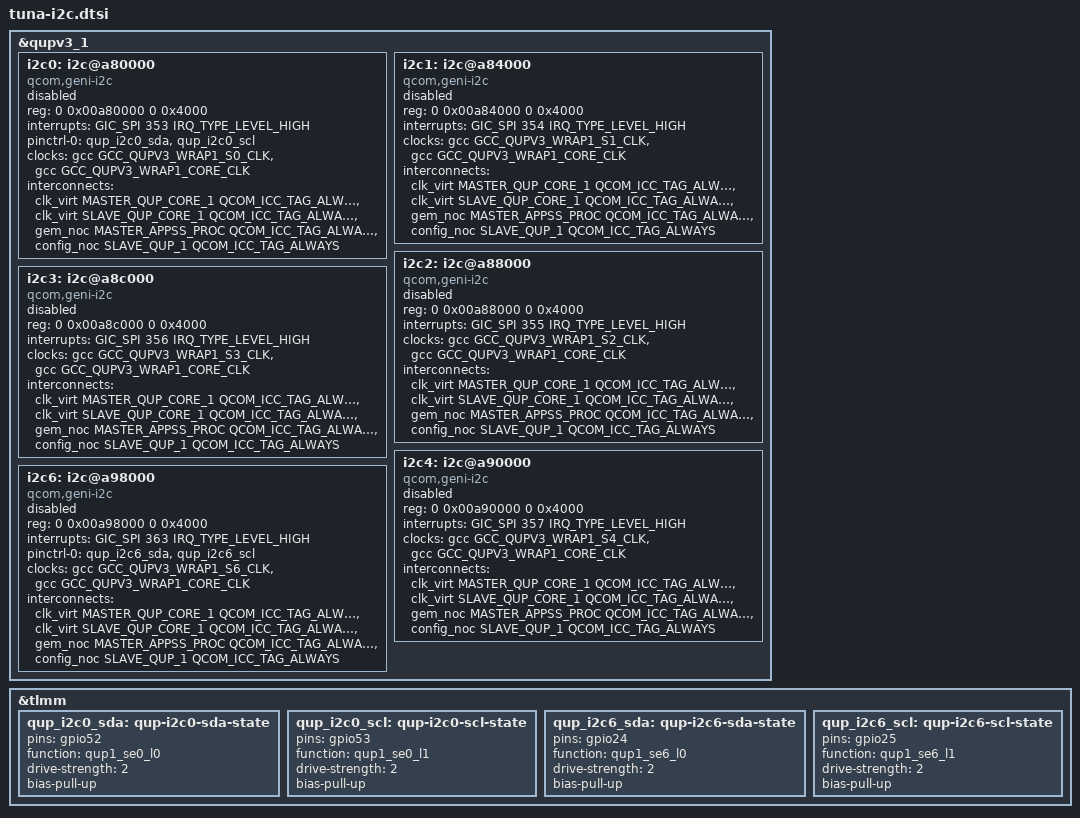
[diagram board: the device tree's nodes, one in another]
// SPDX-License-Identifier: BSD-3-Clause
/*
 * Meizu 22 (M2582) -- the I2C instances inside qupv3 wrap 1.
 *
 * tuna.dtsi already declares qupv3_1 at 0xac0000 and uart7 (SE7) inside it.
 * This adds the I2C controllers that share that wrapper. Addresses and
 * interrupts are taken from the factory device tree, which names the same
 * blocks "qcom,i2c-geni" and calls the clock "se-clk":
 *
 *     SE0  0xa80000  GIC SPI 353   gpio52/53   <- the only one enabled here
 *     SE1  0xa84000  GIC SPI 354   gpio4/5     <- absent from the AP's map
 *     SE2  0xa88000  GIC SPI 355   gpio8/9
 *     SE3  0xa8c000  GIC SPI 356   gpio60/61   (WCD939x codec, factory only)
 *     SE4  0xa90000  GIC SPI 357   gpio16/17
 *     SE6  0xa98000  GIC SPI 363   gpio24/25   <- absent from the AP's map
 *     SE7  0xa9c000  GIC SPI 579   (uart7, declared in tuna.dtsi)
 *
 * The pin numbers are mainline's, from pinctrl-tuna.c, and the factory tree's
 * agree with them instance for instance: its SE0 is on gpio52/53, its SE5 on
 * gpio12/13, its SE6 on gpio24/25. An earlier note here claimed the two tables
 * were offset; that came from a scan which matched the string "gpio" in every
 * pin property of each state node instead of the first, so the factory's SE0
 * read back as gpio28/29. One block at a time gives gpio52/53. Nothing on this
 * board is wired to SE0 or to any other bus in this wrapper -- see
 * meizu-m2582-i2c.dtsi for where the devices actually are.
 *
 * Every instance needs both clocks named. qcom-geni-se.c takes "se" with
 * devm_clk_get() and "core" with devm_clk_get_optional() and enables both
 * before touching a register; with "core" missing the enable silently
 * succeeds on a NULL pointer, the QUP core stays unclocked, and the first
 * register read raises a synchronous external abort.
 *
 * Every instance votes for the QUP core path as well. geni_icc_get() treats the
 * paths as optional, which is a trap here: without a vote on
 * MASTER_QUP_CORE_1 -> SLAVE_QUP_CORE_1 the wrap's QUP core clock is gated, and
 * the first transfer through the controller then wedges the AXI bus. The paths
 * were left out originally on the theory that configuring one made the probe
 * abort; that abort was SE6's dead register window, which is a different
 * problem and is documented below.
 */

&qupv3_1 {
	i2c0: i2c@a80000 {
		compatible = "qcom,geni-i2c";
		reg = <0 0x00a80000 0 0x4000>;
		interrupts = <GIC_SPI 353 IRQ_TYPE_LEVEL_HIGH>;
		/*
		 * SDA/SCL on gpio52/gpio53. SE1 and SE6 are not mapped for the
		 * application processor at all -- the first register access to
		 * either raises a synchronous external abort -- so this is the
		 * bus to use.
		 */
		pinctrl-names = "default";
		pinctrl-0 = <&qup_i2c0_sda>, <&qup_i2c0_scl>;
		clocks = <&gcc GCC_QUPV3_WRAP1_S0_CLK>, <&gcc GCC_QUPV3_WRAP1_CORE_CLK>;
		interconnects = <&clk_virt MASTER_QUP_CORE_1 QCOM_ICC_TAG_ALWAYS
				 &clk_virt SLAVE_QUP_CORE_1 QCOM_ICC_TAG_ALWAYS>,
				<&gem_noc MASTER_APPSS_PROC QCOM_ICC_TAG_ALWAYS
				 &config_noc SLAVE_QUP_1 QCOM_ICC_TAG_ALWAYS>;
		interconnect-names = "qup-core", "qup-config";
		clock-names = "se", "core";
		status = "disabled";
	};

	i2c1: i2c@a84000 {
		compatible = "qcom,geni-i2c";
		reg = <0 0x00a84000 0 0x4000>;
		interrupts = <GIC_SPI 354 IRQ_TYPE_LEVEL_HIGH>;
		clocks = <&gcc GCC_QUPV3_WRAP1_S1_CLK>, <&gcc GCC_QUPV3_WRAP1_CORE_CLK>;
		interconnects = <&clk_virt MASTER_QUP_CORE_1 QCOM_ICC_TAG_ALWAYS
				 &clk_virt SLAVE_QUP_CORE_1 QCOM_ICC_TAG_ALWAYS>,
				<&gem_noc MASTER_APPSS_PROC QCOM_ICC_TAG_ALWAYS
				 &config_noc SLAVE_QUP_1 QCOM_ICC_TAG_ALWAYS>;
		interconnect-names = "qup-core", "qup-config";
		clock-names = "se", "core";
		status = "disabled";
	};

	i2c2: i2c@a88000 {
		compatible = "qcom,geni-i2c";
		reg = <0 0x00a88000 0 0x4000>;
		interrupts = <GIC_SPI 355 IRQ_TYPE_LEVEL_HIGH>;
		clocks = <&gcc GCC_QUPV3_WRAP1_S2_CLK>, <&gcc GCC_QUPV3_WRAP1_CORE_CLK>;
		interconnects = <&clk_virt MASTER_QUP_CORE_1 QCOM_ICC_TAG_ALWAYS
				 &clk_virt SLAVE_QUP_CORE_1 QCOM_ICC_TAG_ALWAYS>,
				<&gem_noc MASTER_APPSS_PROC QCOM_ICC_TAG_ALWAYS
				 &config_noc SLAVE_QUP_1 QCOM_ICC_TAG_ALWAYS>;
		interconnect-names = "qup-core", "qup-config";
		clock-names = "se", "core";
		status = "disabled";
	};

	i2c3: i2c@a8c000 {
		compatible = "qcom,geni-i2c";
		reg = <0 0x00a8c000 0 0x4000>;
		interrupts = <GIC_SPI 356 IRQ_TYPE_LEVEL_HIGH>;
		clocks = <&gcc GCC_QUPV3_WRAP1_S3_CLK>, <&gcc GCC_QUPV3_WRAP1_CORE_CLK>;
		interconnects = <&clk_virt MASTER_QUP_CORE_1 QCOM_ICC_TAG_ALWAYS
				 &clk_virt SLAVE_QUP_CORE_1 QCOM_ICC_TAG_ALWAYS>,
				<&gem_noc MASTER_APPSS_PROC QCOM_ICC_TAG_ALWAYS
				 &config_noc SLAVE_QUP_1 QCOM_ICC_TAG_ALWAYS>;
		interconnect-names = "qup-core", "qup-config";
		clock-names = "se", "core";
		status = "disabled";
	};

	i2c4: i2c@a90000 {
		compatible = "qcom,geni-i2c";
		reg = <0 0x00a90000 0 0x4000>;
		interrupts = <GIC_SPI 357 IRQ_TYPE_LEVEL_HIGH>;
		clocks = <&gcc GCC_QUPV3_WRAP1_S4_CLK>, <&gcc GCC_QUPV3_WRAP1_CORE_CLK>;
		interconnects = <&clk_virt MASTER_QUP_CORE_1 QCOM_ICC_TAG_ALWAYS
				 &clk_virt SLAVE_QUP_CORE_1 QCOM_ICC_TAG_ALWAYS>,
				<&gem_noc MASTER_APPSS_PROC QCOM_ICC_TAG_ALWAYS
				 &config_noc SLAVE_QUP_1 QCOM_ICC_TAG_ALWAYS>;
		interconnect-names = "qup-core", "qup-config";
		clock-names = "se", "core";
		status = "disabled";
	};

	i2c6: i2c@a98000 {
		compatible = "qcom,geni-i2c";
		reg = <0 0x00a98000 0 0x4000>;
		interrupts = <GIC_SPI 363 IRQ_TYPE_LEVEL_HIGH>;
		/*
		 * geni_se_resources_on() ends with
		 * pinctrl_pm_select_default_state(), so without these the SDA/SCL pads
		 * stay in whatever the bootloader left them in and no traffic is
		 * possible even if the controller probes. The functions exist in
		 * pinctrl-tuna.c as msm_mux_qup1_se6_l0 (gpio24) and _l1 (gpio25).
		 * The factory tree says gpio40/gpio41 for the same function, which is
		 * how we learned that its pin numbers, like its clock numbers, are its
		 * own and do not line up with the mainline binding.
		 */
		pinctrl-names = "default";
		pinctrl-0 = <&qup_i2c6_sda>, <&qup_i2c6_scl>;
		clocks = <&gcc GCC_QUPV3_WRAP1_S6_CLK>, <&gcc GCC_QUPV3_WRAP1_CORE_CLK>;
		interconnects = <&clk_virt MASTER_QUP_CORE_1 QCOM_ICC_TAG_ALWAYS
				 &clk_virt SLAVE_QUP_CORE_1 QCOM_ICC_TAG_ALWAYS>,
				<&gem_noc MASTER_APPSS_PROC QCOM_ICC_TAG_ALWAYS
				 &config_noc SLAVE_QUP_1 QCOM_ICC_TAG_ALWAYS>;
		interconnect-names = "qup-core", "qup-config";
		clock-names = "se", "core";
		status = "disabled";
	};
};

/*
 * The two dead windows, and how the rest of the wrapper was cleared.
 *
 * This block replaces five rounds of wrong theories. The short version: SE6 at
 * 0xa98000, the instance this file originally enabled, cannot be read from the
 * application processor at all, so the driver's first register access after
 * ioremap raised a synchronous external abort long before any clock, pinctrl or
 * interconnect code could matter. Switching to SE0 fixed it on the first try.
 *
 * How to tell a dead window from a live one, without panicking the board:
 * read it from userspace through /dev/mem. That mapping is Normal memory, not
 * Device, so a window the bus does not answer raises SIGBUS and kills only the
 * reading process -- the kernel is untouched. One address per child process,
 * O_RDONLY (O_RDWR on the same page hangs the process instead of failing):
 *
 *     python3 -c "import mmap,os,struct,sys; *     phys=int(sys.argv[1],16); base=phys&~0xfff; *     fd=os.open('/dev/mem',os.O_RDONLY|os.O_SYNC); *     m=mmap.mmap(fd,0x1000,mmap.MAP_SHARED,mmap.PROT_READ,offset=base); *     print('0x%08x'%struct.unpack('<I',m[phys-base:phys-base+4])[0])" 0xa80000
 *
 * Measured that way, all of qupv3 wrap 1:
 *
 *     SE0 0xa80000  0x00000009   live
 *     SE1 0xa84000  SIGBUS       DEAD
 *     SE2 0xa88000  0x00000009   live
 *     SE3 0xa8c000  0x00000009   live  (the factory kernel's bus, WCD939x)
 *     SE4 0xa90000  0x00000009   live
 *     SE6 0xa98000  SIGBUS       DEAD  (what this file used to enable)
 *     SE7 0xa9c000  0x0000000a   live  (uart7)
 *
 * SE1 and SE6 are absent from the AP's address map, most likely because they
 * belong to the secure world. The factory device tree agrees that this board
 * does not use SE6 as an I2C bus: it leaves i2c@a98000 disabled and enables
 * only se3, for the codec.
 *
 * Everything else that was suspected and is now known to be irrelevant: the
 * "core" clock, the interconnect votes, the factory's clock and pin numbering,
 * and a supposedly closed GCC block. The GCC QUP registers are in fact readable
 * (0x162000 reads, and clk_summary shows the kernel enabled those clocks), and
 * the pin numbering was right all along -- gpio24/25 really are SE6, which is
 * simply the wrong bus to be on.
 */
&tlmm {
	/*
	 * SE0's pads (see the note on i2c0 above for why this is the bus to use).
	 * pinctrl-tuna.c has qup1_se0_l0 on gpio52 and qup1_se0_l1 on gpio53.
	 */
	qup_i2c0_sda: qup-i2c0-sda-state {
		pins = "gpio52";
		function = "qup1_se0_l0";
		drive-strength = <2>;
		bias-pull-up;
	};

	qup_i2c0_scl: qup-i2c0-scl-state {
		pins = "gpio53";
		function = "qup1_se0_l1";
		drive-strength = <2>;
		bias-pull-up;
	};

	qup_i2c6_sda: qup-i2c6-sda-state {
		pins = "gpio24";
		function = "qup1_se6_l0";
		drive-strength = <2>;
		bias-pull-up;
	};

	qup_i2c6_scl: qup-i2c6-scl-state {
		pins = "gpio25";
		function = "qup1_se6_l1";
		drive-strength = <2>;
		bias-pull-up;
	};
};

/*
 * The two dead windows, revisited.
 *
 * The abort was never about pin numbering or clock IDs. Both were suspected and
 * both were disproved: the factory tree's pin numbers agree with mainline's
 * (gpio52/53 for SE0, gpio24/25 for SE6), and its SE clock IDs agree too --
 * <&gcc 0x59> for the bus this board runs is GCC_QUPV3_WRAP2_S0_CLK in
 * qcom,gcc-tuna.h, and 0x6d/0x6e for its wrapper are
 * GCC_QUPV3_WRAP_2_M/S_AHB_CLK. The abort was SE6's window not answering the
 * AP at all, which is what the measurements above show.
 */
